VERSION ""

NS_ :

BS_:

BU_: Motor_01 GearBox_01 Diagnosis GearActuator_01 SecurityStatus_01 SMLS_01 BCM_01

BO_ 3221225472 VECTOR__INDEPENDENT_SIG_MSG: 0 Vector__XXX
 SG_ GearBoxStatus : 0|8@1- (1,0) [0|1] "" Vector__XXX

BO_ 1281 GearBoxStatus_01: 8 GearBox_01
 SG_ GearBox_Position : 0|8@1+ (1,0) [0|255] "" Vector__XXX

BO_ 1911 Diagnosis_01: 8 Diagnosis
 SG_ System_Status : 8|1@1+ (1,0) [0|1] "" Vector__XXX
 SG_ MotorState : 0|8@1+ (1,0) [0|255] "" Vector__XXX

BO_ 1120 GearActuator_01: 8 GearActuator_01
 SG_ GearBox_Position : 0|8@1+ (1,0) [0|255] "" Vector__XXX

BO_ 1024 SecurityStatus_01: 8 SecurityStatus_01
 SG_ KeyPosition : 0|8@1+ (1,0) [0|255] "" Vector__XXX

BO_ 1280 MotorStatus_01: 8 Motor_01
 SG_ MotorState : 0|8@1+ (1,0) [0|255] "" Vector__XXX

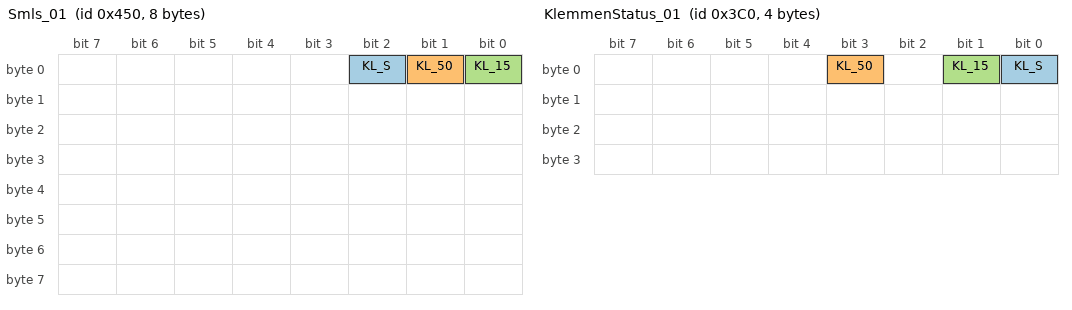
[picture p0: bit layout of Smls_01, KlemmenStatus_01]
BO_ 1104 Smls_01: 8 SMLS_01
 SG_ KL_S : 2|1@1+ (1,0) [0|1] "" Vector__XXX
 SG_ KL_50 : 1|1@1+ (1,0) [0|1] "" Vector__XXX
 SG_ KL_15 : 0|1@1+ (1,0) [0|1] "" Vector__XXX

BO_ 960 KlemmenStatus_01: 4 BCM_01
 SG_ KL_S : 0|1@1+ (1,0) [0|1] "" Vector__XXX
 SG_ KL_50 : 3|1@1+ (1,0) [0|1] "" Vector__XXX
 SG_ KL_15 : 1|1@1+ (1,0) [0|1] "" Vector__XXX

EV_ env_KL_Status: 0 [0|15] "" 0 1 DUMMY_NODE_VECTOR3 Vector__XXX;

EV_ env_Key_In: 0 [0|1] "" 0 2 DUMMY_NODE_VECTOR3 Vector__XXX;

EV_ env_Key_Near: 0 [0|1] "" 0 3 DUMMY_NODE_VECTOR3 Vector__XXX;

EV_ env_Key_Out: 0 [0|1] "" 0 4 DUMMY_NODE_VECTOR3 Vector__XXX;

EV_ env_PositionGB_Error: 0 [0|1] "" 0 5 DUMMY_NODE_VECTOR3 Vector__XXX;

EV_ env_PositionGB_R: 0 [0|1] "" 0 6 DUMMY_NODE_VECTOR3 Vector__XXX;

EV_ env_PositionGB_S: 0 [0|1] "" 0 7 DUMMY_NODE_VECTOR3 Vector__XXX;

EV_ env_PositionGB_D: 0 [0|1] "" 0 8 DUMMY_NODE_VECTOR3 Vector__XXX;

EV_ env_PositionGB_N: 0 [0|1] "" 0 9 DUMMY_NODE_VECTOR0 Vector__XXX;

EV_ env_PositionGB_P: 0 [0|1] "" 0 10 DUMMY_NODE_VECTOR3 Vector__XXX;

EV_ env_PositionGB_Unknown: 0 [0|1] "" 0 11 DUMMY_NODE_VECTOR3 Vector__XXX;

EV_ env_GearBoxPosition: 0 [0|15] "" 0 12 DUMMY_NODE_VECTOR3 Vector__XXX;

EV_ env_System_Status: 0 [0|1] "" 0 13 DUMMY_NODE_VECTOR3 Vector__XXX;

EV_ env_MotorState: 0 [0|1] "" 0 14 DUMMY_NODE_VECTOR3 Vector__XXX;

EV_ env_KL50: 0 [0|1] "" 0 15 DUMMY_NODE_VECTOR3 Vector__XXX;

EV_ env_KL15: 0 [0|1] "" 0 16 DUMMY_NODE_VECTOR3 Vector__XXX;

EV_ env_KLS: 0 [0|1] "" 0 17 DUMMY_NODE_VECTOR3 Vector__XXX;

EV_ env_KeyPosition: 0 [0|15] "" 0 18 DUMMY_NODE_VECTOR3 Vector__XXX;

CM_ BO_ 3221225472 "This is a message for not used signals, created by Vector CANdb++ DBC OLE DB Provider.";
